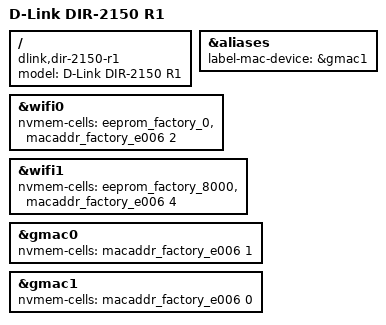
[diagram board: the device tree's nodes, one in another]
// SPDX-License-Identifier: GPL-2.0-or-later OR MIT

#include "mt7621_dlink_dir-xxxx-xx.dtsi"
#include "mt7621_dlink_flash-128m-r1.dtsi"

/ {
	compatible = "dlink,dir-2150-r1", "mediatek,mt7621-soc";
	model = "D-Link DIR-2150 R1";
};

&aliases {
	label-mac-device = &gmac1;
};

&wifi0 {
	nvmem-cells = <&eeprom_factory_0>, <&macaddr_factory_e006 2>;
};

&wifi1 {
	nvmem-cells = <&eeprom_factory_8000>, <&macaddr_factory_e006 4>;
};

&gmac0 {
	nvmem-cells = <&macaddr_factory_e006 1>;
};

&gmac1 {
	nvmem-cells = <&macaddr_factory_e006 0>;
};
